# RL6845_IP_SVD register map
Vendor: Realtek
Registers are 32-bit, read-write, reset 0x0 unless marked. A register's access mark holds for its fields unless they carry their own. Offsets are from the block's base; [hi:lo] are bit positions; {n}, {i} and the like mark numbered series; <NAME> marks a mode.

## CMP_REG
Base 0x41011800
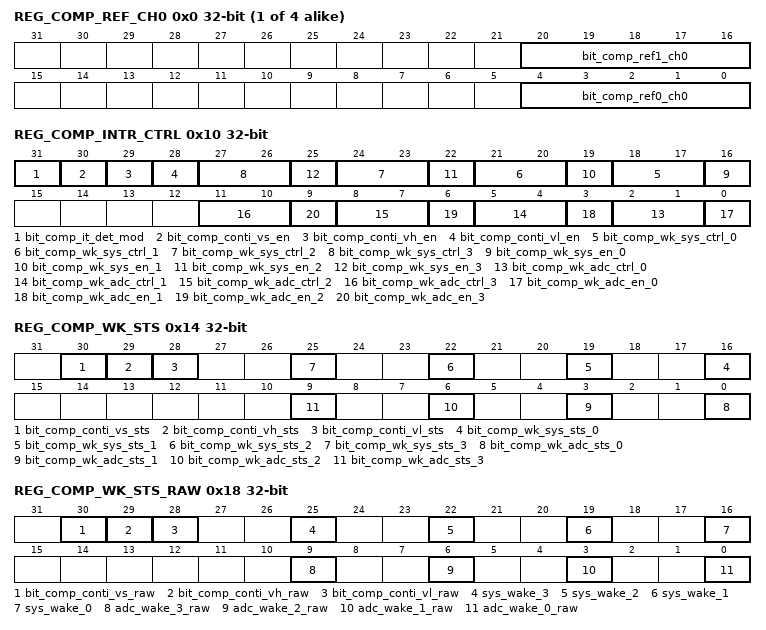
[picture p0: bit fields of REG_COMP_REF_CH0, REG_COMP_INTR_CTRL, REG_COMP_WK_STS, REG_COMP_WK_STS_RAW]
{0x0+4i} REG_COMP_REF_CH{i} (i=0..3) — Comparator Channel {i} Reference Voltage Register
  [20:16] bit_comp_ref1_ch{i} — This field controls the comparator channel {i} internal reference voltage 1. Vref1 is equal to (the value of bit_comp_ref1)*0.1V. Therefore, when bit_comp_ref1 is 5, Vref1 is 0.5V. Vref1 is used as high level thredshold, so user must keep Vref1 >= Vref0.
  [4:0] bit_comp_ref0_ch{i} — This field controls the comparator channel {i} internal reference voltage 0. Vref0 is equal to (the value of bit_comp_ref0)*0.1V. Therefore, when bit_comp_ref0 is 5, Vref0 is 0.5V. Vref0 is used as low level thredshold, so user must keep Vref1 >= Vref0.
0x10 REG_COMP_INTR_CTRL — Comparator Interrupt Control Register
  [31] bit_comp_it_det_mod — This bit controls the interrupt bit_comp_wk* operation. comparison criterion matching is rising edge or not. 0: The detection mode is level detection. when the comparison criterion is match, bit_comp_wk* will send interrupt continuously. 1: The detection mode is edge detection. when the comparison criterion is match, bit_comp_wk* will send interrupt once at the time of matching.
  [30] bit_comp_conti_vs_en — At continuous mode, channel Vref hysteresis level rising interrupt. 0:disable; 1:enable
  [29] bit_comp_conti_vh_en — At continuous mode, channel Vref high level rising interrupt. 0:disable; 1:enable
  [28] bit_comp_conti_vl_en — At continuous mode, channel Vref low level rising interrupt. 0:disable; 1:enable
  [3n+18:3n+17] bit_comp_wk_sys_ctrl_{n} (n=0..3) — This field defines the criterion of when comparator channel {n} should wake up system. The comparator should send wakeup signal only when bit_comp_wk_sys_en is 1, if the criterion matches. 0: When Vin < Vref0, the comparator wakes up system. 1: When Vin >= Vref1, the comparator wakes up system. 2: When Vin > Vref0 and Vin < Vref1, the comparator wakes up system.
  [3n+16] bit_comp_wk_sys_en_{n} (n=0..3) — This bit controls whether the comparator channel {n} sends wakeup signal or not when the criterion of bit_comp_wk_sys_ctrl matches. 0: Disable comparator wakes up system. 1: Enable comparator wakes up system.
  [3n+2:3n+1] bit_comp_wk_adc_ctrl_{n} (n=0..3) — This field defines the criterion of when comparator channel {n} should wake up ADC. The comparator should send wakeup signal only when bit_comp_wk_adc_en is 1, if the criterion matches. 0: When Vin < Vref0, the comparator wakes up ADC. 1: When Vin >= Vref1, the comparator wakes up ADC. 2: When Vin > Vref0 and Vin < Vref1, the comparator wakes up ADC.
  [3n] bit_comp_wk_adc_en_{n} (n=0..3) — This bit controls whether the comparator channel {n} sends wakeup signal or not when the criterion of bit_comp_wk_adc_ctrl matches. 0: Disable comparator wakes up ADC. 1: Enable comparator wakes up ADC.
0x14 REG_COMP_WK_STS ro — Comparator Wakeup ADC/SYS Status Register
  [30] bit_comp_conti_vs_sts — At continuous mode, channel Vref hysteresis level rising interrupt status
  [29] bit_comp_conti_vh_sts — At continuous mode, channel Vref high level rising interrupt status
  [28] bit_comp_conti_vl_sts — At continuous mode, channel Vref low level rising interrupt status
  [3n+16] bit_comp_wk_sys_sts_{n} (n=0..3) — Channel {n} system wakeup status
  [3n] bit_comp_wk_adc_sts_{n} (n=0..3) — Channel {n} ADC wakeup status
0x18 REG_COMP_WK_STS_RAW ro — Comparator Wakeup Register
  [30] bit_comp_conti_vs_raw — At continuous mode, channel Vref hysteresis level rising interrupt status raw
  [29] bit_comp_conti_vh_raw — At continuous mode, channel Vref high level rising interrupt status raw
  [28] bit_comp_conti_vl_raw — At continuous mode, channel Vref low level rising interrupt status raw
  [25] sys_wake_3 — Channle 3 system wakeup status raw
  [22] sys_wake_2 — Channel 2 system wakeup status raw
  [19] sys_wake_1 — Channle 1 system wakeup status raw
  [16] sys_wake_0 — Channle 0 system wakeup status raw
  [9] adc_wake_3_raw — Channle 3 ADC wakeup status raw
  [6] adc_wake_2_raw — Channel 2 ADC wakeup status raw
  [3] adc_wake_1_raw — Channle 1 ADC wakeup status raw
  [0] adc_wake_0_raw — Channle 0 ADC wakeup status raw
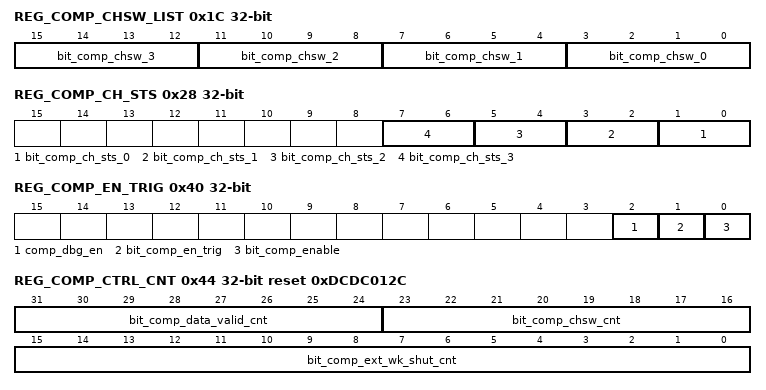
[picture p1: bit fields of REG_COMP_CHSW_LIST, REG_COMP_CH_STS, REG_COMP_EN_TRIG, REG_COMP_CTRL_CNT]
0x1C REG_COMP_CHSW_LIST — Comparator Channel Switch List Register
  [4n+3:4n] bit_comp_chsw_{n} (n=0..3) — This field defines the channel {n} to do a comparison when the start-compare event takes place.
0x20 REG_COMP_LAST_CH ro — Comparator Last Channel Register
  [1:0] bit_comp_last_ch — Last channel used
0x24 REG_COMP_BUSY_STS ro — Comparator Busy Status Register
  [0] bit_comp_busy_sts — This bit reflects whether the comparatos is busy or not. 0: The comparatos is ready. 1: The comparator is busy.
0x28 REG_COMP_CH_STS ro — Comparator Channel Status Register
  [2n+1:2n] bit_comp_ch_sts_{n} (n=0..3) — This field reflects the channel {n} comparison result. 0: When Vin < Vref0. 1: When Vin >= Vref1. 2: When Vin > Vref0 and Vin < Vref1.
0x2C REG_COMP_AUTO_SHUT — Comparator Automatic Shut Register
  [0] bit_comp_auto_shut — This bit controls the comparator to disable the analog module and mux automatically or not after the analog conversion is done. 0: The analog module and mux will NOT be disabled. 1: The analog module and mux will be disabled automatically after the analog conversion is done.
0x30 REG_COMP_EXT_TRIG_CTRL — Comparator External Trigger Control Register
  [0] bit_comp_ext_wk_timer — This bit controls the external trigger source of general timer enabled or not. If it's enabled, the comparator would execute comparison process when the timer event sends to comparator module. 0: Disable external timer trigger. 1: Enable external timer trigger.
0x34 REG_COMP_EXT_TRIG_TIMER_SEL — Comparator External Trigger Timer Select Register
  [2:0] bit_comp_ext_wk_timer_sel — This field defines which timer channel would be used to wake up the comparator. 0: timer module 0 is used as the comparator external trigger source. 1:timer module 1 is used as the comparator external trigger source. ...so on... 7:timer module 7 is used as the comparator external trigger source.
0x38 REG_COMP_RST_LIST — Comparator Reset Channel List Register
  [0] bit_comp_rst_list — This bit controls to reset the channel switch to default state or not. Once this bit is set, the auto/manual channel switch goes to the first channel as a default state. 0: Do Not reset conversion list to default state. 1:Reset conversion list to default state.
0x3C REG_COMP_AUTOSW_EN — Comparator Automatic Channel Switch Enable Register
  [0] bit_comp_autosw_en — This bit controls the automatic channel switch enabled or disabled. 0: Disable the automatic channel switch. If an automatic channel switch is in process, writing 0 will terminate the automatic channel switch. 1: Enable the automatic channel switch. When setting this bit, an automatic channel switch starts from the first channel in the channel switch list.
0x40 REG_COMP_EN_TRIG — Comparator Enable Trigger Register
  [2] comp_dbg_en — The comparator IP debug port enable.
  [1] bit_comp_en_trig — This bit controls the analog module and the analog mux of comparator to be enabled or not. Every time this bit is written, the comparator switches to a new channel and does one comparison. After this, it shuts down the analog module according to REG_COMP_AUTO_SHUT. Therefore, this bit can be used as a start-compare event which is controlled by software. Every time a comparison is done, software must clear this bit manually. 0: Disable the analog module and analog mux. 1: Enable the analog module and analog mux, then start a new channel comparison.
  [0] bit_comp_enable — The comparator IP internal enable.
0x44 REG_COMP_CTRL_CNT reset 0xDCDC012C — Comparator External Wake Shut Count Register
  [31:24] bit_comp_data_valid_cnt — This field defines how long the comparator analog module data is valid for digital module after analog module works. It's about 55us.
  [23:16] bit_comp_chsw_cnt — This field defines how long the channel switch can jump to next channel at automatic channel switch mode. It's about 55us.
  [15:0] bit_comp_ext_wk_shut_cnt — This field defines how long to disable comparator analog module when an external trigger event is sent to the comparator. The count must include the comparator response time to get a correct compare result.It's about 75us.
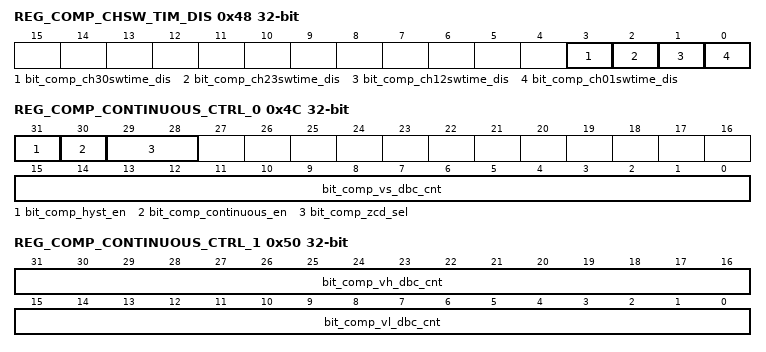
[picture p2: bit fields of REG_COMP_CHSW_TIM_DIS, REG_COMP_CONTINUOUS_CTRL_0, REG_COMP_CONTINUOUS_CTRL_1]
0x48 REG_COMP_CHSW_TIM_DIS — Comparator Channel Switch Time Disable Register
  [3] bit_comp_ch30swtime_dis — This field defines whether disable the channel switch time(bit_comp_chsw_cnt) from channel list 3 to 0, only valid in auto mode
  [2] bit_comp_ch23swtime_dis — This field defines whether disable the channel switch time(bit_comp_chsw_cnt) from channel list 2 to 3, only valid in auto mode
  [1] bit_comp_ch12swtime_dis — This field defines whether disable the channel switch time(bit_comp_chsw_cnt) from channel list 1 to 2, only valid in auto mode
  [0] bit_comp_ch01swtime_dis — This field defines whether disable the channel switch time(bit_comp_chsw_cnt) from channel list 0 to 1, only valid in auto mode
0x4C REG_COMP_CONTINUOUS_CTRL_0 — Comparator Continuous Control Register 0
  [31] bit_comp_hyst_en — enable comparator hysteresis circuit function. hysteresis circuit function can only take effect in continuous function.
  [30] bit_comp_continuous_en — enable comparator continuous sample function. continuous sample function can only take effect in autoswitch mode with autoshut is disabled, and 4 channels in list are must configured into same channel
  [29:28] bit_comp_zcd_sel — select output ZCD signals source: 00: none ; 01: comp out Vref1; 10: comp out Vref0; 11: comp hysteresis
  [15:0] bit_comp_vs_dbc_cnt — hysteresis debounce counter for ZCD
0x50 REG_COMP_CONTINUOUS_CTRL_1 — Comparator Continuous Control Register 1
  [31:16] bit_comp_vh_dbc_cnt — Vref high level debounce counter for ZCD
  [15:0] bit_comp_vl_dbc_cnt — Vref low level debounce counter for ZCD
0x54 REG_COMP_DUMMY reset 0xFFFF — Comparator Dummy Register
